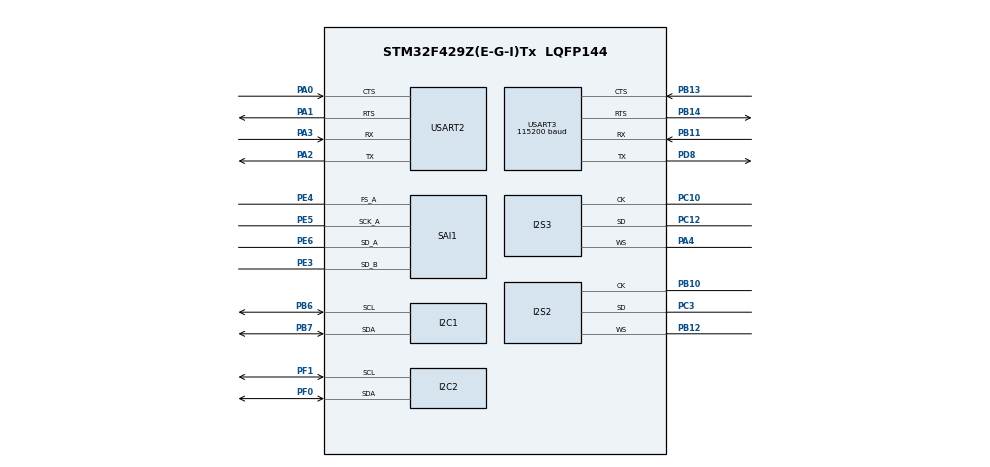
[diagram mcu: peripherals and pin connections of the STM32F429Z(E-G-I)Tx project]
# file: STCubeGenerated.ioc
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Dma.Request0=SPI3_RX
Dma.Request1=SPI2_RX
Dma.Request2=SAI1_A
Dma.Request3=SAI1_B
Dma.SAI1_A.2.Channel=DMA_CHANNEL_0
Dma.SAI1_A.2.Direction=DMA_PERIPH_TO_MEMORY
Dma.SAI1_A.2.FIFOMode=DMA_FIFOMODE_ENABLE
Dma.SAI1_A.2.FIFOThreshold=DMA_FIFO_THRESHOLD_HALFFULL
Dma.SAI1_A.2.Instance=DMA2_Stream1
Dma.SAI1_A.2.MemBurst=DMA_MBURST_SINGLE
Dma.SAI1_A.2.MemDataAlignment=DMA_MDATAALIGN_WORD
Dma.SAI1_A.2.MemInc=DMA_MINC_ENABLE
Dma.SAI1_A.2.Mode=DMA_CIRCULAR
Dma.SAI1_A.2.PeriphBurst=DMA_PBURST_SINGLE
Dma.SAI1_A.2.PeriphDataAlignment=DMA_PDATAALIGN_WORD
Dma.SAI1_A.2.PeriphInc=DMA_PINC_DISABLE
Dma.SAI1_A.2.Priority=DMA_PRIORITY_LOW
Dma.SAI1_B.3.Channel=DMA_CHANNEL_1
Dma.SAI1_B.3.Direction=DMA_PERIPH_TO_MEMORY
Dma.SAI1_B.3.FIFOMode=DMA_FIFOMODE_ENABLE
Dma.SAI1_B.3.FIFOThreshold=DMA_FIFO_THRESHOLD_HALFFULL
Dma.SAI1_B.3.Instance=DMA2_Stream4
Dma.SAI1_B.3.MemBurst=DMA_MBURST_INC4
Dma.SAI1_B.3.MemDataAlignment=DMA_MDATAALIGN_WORD
Dma.SAI1_B.3.MemInc=DMA_MINC_ENABLE
Dma.SAI1_B.3.Mode=DMA_CIRCULAR
Dma.SAI1_B.3.PeriphBurst=DMA_PBURST_INC4
Dma.SAI1_B.3.PeriphDataAlignment=DMA_PDATAALIGN_WORD
Dma.SAI1_B.3.PeriphInc=DMA_PINC_DISABLE
Dma.SAI1_B.3.Priority=DMA_PRIORITY_LOW
Dma.SPI2_RX.1.Channel=DMA_CHANNEL_0
Dma.SPI2_RX.1.Direction=DMA_PERIPH_TO_MEMORY
Dma.SPI2_RX.1.FIFOMode=DMA_FIFOMODE_ENABLE
Dma.SPI2_RX.1.FIFOThreshold=DMA_FIFO_THRESHOLD_HALFFULL
Dma.SPI2_RX.1.Instance=DMA1_Stream3
Dma.SPI2_RX.1.MemBurst=DMA_MBURST_SINGLE
Dma.SPI2_RX.1.MemDataAlignment=DMA_MDATAALIGN_WORD
Dma.SPI2_RX.1.MemInc=DMA_MINC_ENABLE
Dma.SPI2_RX.1.Mode=DMA_CIRCULAR
Dma.SPI2_RX.1.PeriphBurst=DMA_PBURST_SINGLE
Dma.SPI2_RX.1.PeriphDataAlignment=DMA_PDATAALIGN_HALFWORD
Dma.SPI2_RX.1.PeriphInc=DMA_PINC_DISABLE
Dma.SPI2_RX.1.Priority=DMA_PRIORITY_LOW
Dma.SPI3_RX.0.Channel=DMA_CHANNEL_0
Dma.SPI3_RX.0.Direction=DMA_PERIPH_TO_MEMORY
Dma.SPI3_RX.0.FIFOMode=DMA_FIFOMODE_ENABLE
Dma.SPI3_RX.0.FIFOThreshold=DMA_FIFO_THRESHOLD_HALFFULL
Dma.SPI3_RX.0.Instance=DMA1_Stream0
Dma.SPI3_RX.0.MemBurst=DMA_MBURST_SINGLE
Dma.SPI3_RX.0.MemDataAlignment=DMA_MDATAALIGN_WORD
Dma.SPI3_RX.0.MemInc=DMA_MINC_ENABLE
Dma.SPI3_RX.0.Mode=DMA_CIRCULAR
Dma.SPI3_RX.0.PeriphBurst=DMA_PBURST_SINGLE
Dma.SPI3_RX.0.PeriphDataAlignment=DMA_PDATAALIGN_HALFWORD
Dma.SPI3_RX.0.PeriphInc=DMA_PINC_DISABLE
Dma.SPI3_RX.0.Priority=DMA_PRIORITY_LOW
I2S2.AudioFreq=I2S_AUDIOFREQ_48K
I2S2.CPOL=I2S_CPOL_LOW
I2S2.DataFormat=I2S_DATAFORMAT_32B
I2S2.ErrorAudioFreq=0.8 %
I2S2.Mode=I2S_MODE_SLAVE_RX
I2S2.RealAudioFreq=48.387 KHz
I2S2.Standard=I2S_STANDARD_MSB
I2S2.VirtualMode=I2S_MODE_SLAVE
I2S3.AudioFreq=I2S_AUDIOFREQ_48K
I2S3.DataFormat=I2S_DATAFORMAT_32B
I2S3.ErrorAudioFreq=0.8 %
I2S3.Mode=I2S_MODE_SLAVE_RX
I2S3.RealAudioFreq=48.387 KHz
I2S3.Standard=I2S_STANDARD_MSB
I2S3.VirtualMode=I2S_MODE_SLAVE
Mcu.Family=STM32F4
Mcu.Name=STM32F429Z(E-G-I)Tx
Mcu.Package=LQFP144
NVIC.DMA1_Stream0_IRQn=true\:0\:0\:false
NVIC.DMA1_Stream3_IRQn=true\:0\:0\:false
NVIC.DMA2_Stream1_IRQn=true\:0\:0\:false
NVIC.DMA2_Stream4_IRQn=true\:0\:0\:false
NVIC.PriorityGroup=NVIC_PRIORITYGROUP_4
PA0/WKUP.Mode=CTS_RTS
PA0/WKUP.Signal=USART2_CTS
PA1.Mode=CTS_RTS
PA1.Signal=USART2_RTS
PA13.Mode=Serial-Wire
PA13.Signal=SYS_JTMS-SWDIO
PA14.Mode=Serial-Wire
PA14.Signal=SYS_JTCK-SWCLK
PA2.Mode=Asynchronous
PA2.Signal=USART2_TX
PA3.Mode=Asynchronous
PA3.Signal=USART2_RX
PA4.Mode=Half_Duplex_Slave
PA4.Signal=I2S3_WS
PB10.Mode=Half_Duplex_Slave
PB10.Signal=I2S2_CK
PB11.Mode=Asynchronous
PB11.Signal=USART3_RX
PB12.Mode=Half_Duplex_Slave
PB12.Signal=I2S2_WS
PB13.Mode=CTS_RTS
PB13.Signal=USART3_CTS
PB14.Mode=CTS_RTS
PB14.Signal=USART3_RTS
PB6.Mode=I2C
PB6.Signal=I2C1_SCL
PB7.Mode=I2C
PB7.Signal=I2C1_SDA
PC10.Mode=Half_Duplex_Slave
PC10.Signal=I2S3_CK
PC12.Mode=Half_Duplex_Slave
PC12.Signal=I2S3_SD
PC3.Mode=Half_Duplex_Slave
PC3.Signal=I2S2_SD
PD8.Mode=Asynchronous
PD8.Signal=USART3_TX
PE3.Mode=SAI_B_SyncSlave
PE3.Signal=SAI1_SD_B
PE4.Mode=SAI_A_AsyncSlave
PE4.Signal=SAI1_FS_A
PE5.Mode=SAI_A_AsyncSlave
PE5.Signal=SAI1_SCK_A
PE6.Mode=SAI_A_AsyncSlave
PE6.Signal=SAI1_SD_A
PF0.Mode=I2C
PF0.Signal=I2C2_SDA
PF1.Mode=I2C
PF1.Signal=I2C2_SCL
ProjectManager.TargetToolchain=MDK-ARM V4
RCC.48MHZClocksFreq_Value=48000000
RCC.AHBFreq_Value=16000000
RCC.APB1Freq_Value=16000000
RCC.APB2Freq_Value=16000000
RCC.CortexFreq_Value=16000000
RCC.HSE_VALUE=25000000
RCC.HSI_VALUE=16000000
RCC.LSE_VALUE=32768
RCC.PLLSAIN=192
RCC.SYSCLKFreq_VALUE=16000000
RCC.VCOOutputFreq_Value=192000000
SAI1.ActiveFrameLength-SAI_A_AsyncSlave=32
SAI1.ActiveFrameLength-SAI_B_SyncSlave=32
SAI1.ClockStrobing-SAI_A_AsyncSlave=SAI_CLOCKSTROBING_RISINGEDGE
SAI1.ClockStrobing-SAI_B_SyncSlave=SAI_CLOCKSTROBING_RISINGEDGE
SAI1.DataSize-SAI_A_AsyncSlave=SAI_DATASIZE_32
SAI1.DataSize-SAI_B_SyncSlave=SAI_DATASIZE_32
SAI1.FIFOThreshold-SAI_A_AsyncSlave=SAI_FIFOTHRESHOLD_HF
SAI1.FIFOThreshold-SAI_B_SyncSlave=SAI_FIFOTHRESHOLD_HF
SAI1.FSDefinition-SAI_A_AsyncSlave=SAI_FS_CHANNEL_IDENTIFICATION
SAI1.FSDefinition-SAI_B_SyncSlave=SAI_FS_CHANNEL_IDENTIFICATION
SAI1.FrameLength-SAI_A_AsyncSlave=64
SAI1.FrameLength-SAI_B_SyncSlave=64
SAI1.Instance-SAI_A_AsyncSlave=SAI$Index_Block_A
SAI1.Instance-SAI_B_SyncSlave=SAI$Index_Block_B
SAI1.Protocol-SAI_B_SyncSlave=SAI_FREE_PROTOCOL
SAI1.SlotActive-SAI_A_AsyncSlave=0xFFFF0000
SAI1.SlotActive-SAI_B_SyncSlave=0xFFFF0000
SAI1.SlotNumber-SAI_A_AsyncSlave=2
SAI1.SlotNumber-SAI_B_SyncSlave=2
SAI1.SlotSize-SAI_A_AsyncSlave=SAI_SLOTSIZE_32B
SAI1.SlotSize-SAI_B_SyncSlave=SAI_SLOTSIZE_32B
SAI1.Synchro-SAI_B_SyncSlave=SAI_SYNCHRONOUS
SAI1.VirtualMode-SAI_A_AsyncSlave=VM_SLAVE
SAI1.VirtualMode-SAI_B_SyncSlave=VM_SLAVE
SAI1.VirtualSlotActive-SAI_A_AsyncSlave=SAI_SLOTACTIVE_ALL
SAI1.VirtualSlotActive-SAI_B_SyncSlave=SAI_SLOTACTIVE_ALL
SAI1.VirtualSlotActive0-SAI_A_AsyncSlave=true
SAI1.VirtualSlotActive0-SAI_B_SyncSlave=false
SAI1.VirtualSlotActive1-SAI_B_SyncSlave=true
USART3.BaudRate=115200

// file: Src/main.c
/**
  ******************************************************************************
  * File Name          : main.c
  * Description        : Main program body
  ******************************************************************************
  *
  * COPYRIGHT(c) 2015 STMicroelectronics
  *
  * Redistribution and use in source and binary forms, with or without modification,
  * are permitted provided that the following conditions are met:
  *   1. Redistributions of source code must retain the above copyright notice,
  *      this list of conditions and the following disclaimer.
  *   2. Redistributions in binary form must reproduce the above copyright notice,
  *      this list of conditions and the following disclaimer in the documentation
  *      and/or other materials provided with the distribution.
  *   3. Neither the name of STMicroelectronics nor the names of its contributors
  *      may be used to endorse or promote products derived from this software
  *      without specific prior written permission.
  *
  * THIS SOFTWARE IS PROVIDED BY THE COPYRIGHT HOLDERS AND CONTRIBUTORS "AS IS"
  * AND ANY EXPRESS OR IMPLIED WARRANTIES, INCLUDING, BUT NOT LIMITED TO, THE
  * IMPLIED WARRANTIES OF MERCHANTABILITY AND FITNESS FOR A PARTICULAR PURPOSE ARE
  * DISCLAIMED. IN NO EVENT SHALL THE COPYRIGHT HOLDER OR CONTRIBUTORS BE LIABLE
  * FOR ANY DIRECT, INDIRECT, INCIDENTAL, SPECIAL, EXEMPLARY, OR CONSEQUENTIAL
  * DAMAGES (INCLUDING, BUT NOT LIMITED TO, PROCUREMENT OF SUBSTITUTE GOODS OR
  * SERVICES; LOSS OF USE, DATA, OR PROFITS; OR BUSINESS INTERRUPTION) HOWEVER
  * CAUSED AND ON ANY THEORY OF LIABILITY, WHETHER IN CONTRACT, STRICT LIABILITY,
  * OR TORT (INCLUDING NEGLIGENCE OR OTHERWISE) ARISING IN ANY WAY OUT OF THE USE
  * OF THIS SOFTWARE, EVEN IF ADVISED OF THE POSSIBILITY OF SUCH DAMAGE.
  *
  ******************************************************************************
  */

#include "stm32f4xx_hal.h"

/* USER CODE BEGIN Includes */
#include "Putz01.h"
/* USER CODE END Includes */

I2C_HandleTypeDef hi2c1;
I2C_HandleTypeDef hi2c2;

I2S_HandleTypeDef hi2s2;
I2S_HandleTypeDef hi2s3;
DMA_HandleTypeDef hdma_spi2_rx;
DMA_HandleTypeDef hdma_spi3_rx;

SAI_HandleTypeDef hsai_BlockA1;
SAI_HandleTypeDef hsai_BlockB1;
DMA_HandleTypeDef hdma_sai1_a;
DMA_HandleTypeDef hdma_sai1_b;

UART_HandleTypeDef huart2;
UART_HandleTypeDef huart3;

void SystemClock_Config(void);
static void MX_GPIO_Init(void);
static void MX_DMA_Init(void);
static void MX_I2C1_Init(void);
static void MX_I2C2_Init(void);
static void MX_I2S2_Init(void);
static void MX_I2S3_Init(void);
static void MX_SAI1_Init(void);
static void MX_USART2_UART_Init(void);
static void MX_USART3_UART_Init(void);

int main(void)
{

  /* MCU Configuration----------------------------------------------------------*/

  /* Reset of all peripherals, Initializes the Flash interface and the Systick. */
  HAL_Init();

  /* Configure the system clock */
  SystemClock_Config();

  /* Initialize all configured peripherals */
  MX_GPIO_Init();
  MX_DMA_Init();
  MX_I2C1_Init();
  MX_I2C2_Init();
  MX_I2S2_Init();
  MX_I2S3_Init();
  MX_SAI1_Init();
  MX_USART2_UART_Init();
  MX_USART3_UART_Init();

  /* USER CODE BEGIN 2 */
	Putz01Init();

  /* USER CODE END 2 */

  /* Infinite loop */
  while (1)
  {
	Putz01Run();

  }

}

/** System Clock Configuration
*/
void SystemClock_Config(void)
{

  RCC_OscInitTypeDef RCC_OscInitStruct;
  RCC_PeriphCLKInitTypeDef PeriphClkInitStruct;

  __HAL_RCC_PLL_PLLM_CONFIG(16);

  __HAL_RCC_PLL_PLLSOURCE_CONFIG(RCC_PLLSOURCE_HSI);

  __PWR_CLK_ENABLE();

  __HAL_PWR_VOLTAGESCALING_CONFIG(PWR_REGULATOR_VOLTAGE_SCALE3);

  RCC_OscInitStruct.OscillatorType = RCC_OSCILLATORTYPE_HSI;
  RCC_OscInitStruct.HSIState = RCC_HSI_ON;
  RCC_OscInitStruct.HSICalibrationValue = 16;
  RCC_OscInitStruct.PLL.PLLState = RCC_PLL_NONE;
  HAL_RCC_OscConfig(&RCC_OscInitStruct);

  PeriphClkInitStruct.PeriphClockSelection = RCC_PERIPHCLK_I2S|RCC_PERIPHCLK_SAI_PLLSAI;
  PeriphClkInitStruct.PLLI2S.PLLI2SN = 192;
  PeriphClkInitStruct.PLLI2S.PLLI2SR = 2;
  PeriphClkInitStruct.PLLSAI.PLLSAIN = 192;
  PeriphClkInitStruct.PLLSAI.PLLSAIQ = 4;
  PeriphClkInitStruct.PLLSAIDivQ = 1;
  HAL_RCCEx_PeriphCLKConfig(&PeriphClkInitStruct);

  HAL_SYSTICK_Config(HAL_RCC_GetHCLKFreq()/1000);

  HAL_SYSTICK_CLKSourceConfig(SYSTICK_CLKSOURCE_HCLK);

}

/* I2C1 init function */
void MX_I2C1_Init(void)
{

  hi2c1.Instance = I2C1;
  hi2c1.Init.ClockSpeed = 100000;
  hi2c1.Init.DutyCycle = I2C_DUTYCYCLE_2;
  hi2c1.Init.OwnAddress1 = 0;
  hi2c1.Init.AddressingMode = I2C_ADDRESSINGMODE_7BIT;
  hi2c1.Init.DualAddressMode = I2C_DUALADDRESS_DISABLED;
  hi2c1.Init.OwnAddress2 = 0;
  hi2c1.Init.GeneralCallMode = I2C_GENERALCALL_DISABLED;
  hi2c1.Init.NoStretchMode = I2C_NOSTRETCH_DISABLED;
  HAL_I2C_Init(&hi2c1);

}

/* I2C2 init function */
void MX_I2C2_Init(void)
{

  hi2c2.Instance = I2C2;
  hi2c2.Init.ClockSpeed = 100000;
  hi2c2.Init.DutyCycle = I2C_DUTYCYCLE_2;
  hi2c2.Init.OwnAddress1 = 0;
  hi2c2.Init.AddressingMode = I2C_ADDRESSINGMODE_7BIT;
  hi2c2.Init.DualAddressMode = I2C_DUALADDRESS_DISABLED;
  hi2c2.Init.OwnAddress2 = 0;
  hi2c2.Init.GeneralCallMode = I2C_GENERALCALL_DISABLED;
  hi2c2.Init.NoStretchMode = I2C_NOSTRETCH_DISABLED;
  HAL_I2C_Init(&hi2c2);

}

/* I2S2 init function */
void MX_I2S2_Init(void)
{

  hi2s2.Instance = SPI2;
  hi2s2.Init.Mode = I2S_MODE_SLAVE_RX;
  hi2s2.Init.Standard = I2S_STANDARD_MSB;
  hi2s2.Init.DataFormat = I2S_DATAFORMAT_32B;
  hi2s2.Init.MCLKOutput = I2S_MCLKOUTPUT_DISABLE;
  hi2s2.Init.AudioFreq = I2S_AUDIOFREQ_48K;
  hi2s2.Init.CPOL = I2S_CPOL_LOW;
  hi2s2.Init.ClockSource = I2S_CLOCK_PLL;
  hi2s2.Init.FullDuplexMode = I2S_FULLDUPLEXMODE_DISABLE;
  HAL_I2S_Init(&hi2s2);

}

/* I2S3 init function */
void MX_I2S3_Init(void)
{

  hi2s3.Instance = SPI3;
  hi2s3.Init.Mode = I2S_MODE_SLAVE_RX;
  hi2s3.Init.Standard = I2S_STANDARD_MSB;
  hi2s3.Init.DataFormat = I2S_DATAFORMAT_32B;
  hi2s3.Init.MCLKOutput = I2S_MCLKOUTPUT_DISABLE;
  hi2s3.Init.AudioFreq = I2S_AUDIOFREQ_48K;
  hi2s3.Init.CPOL = I2S_CPOL_LOW;
  hi2s3.Init.ClockSource = I2S_CLOCK_PLL;
  hi2s3.Init.FullDuplexMode = I2S_FULLDUPLEXMODE_DISABLE;
  HAL_I2S_Init(&hi2s3);

}

/* SAI1 init function */
void MX_SAI1_Init(void)
{

  hsai_BlockA1.Instance = SAI1_Block_A;
  hsai_BlockA1.Init.Protocol = SAI_FREE_PROTOCOL;
  hsai_BlockA1.Init.AudioMode = SAI_MODESLAVE_RX;
  hsai_BlockA1.Init.DataSize = SAI_DATASIZE_32;
  hsai_BlockA1.Init.FirstBit = SAI_FIRSTBIT_MSB;
  hsai_BlockA1.Init.ClockStrobing = SAI_CLOCKSTROBING_RISINGEDGE;
  hsai_BlockA1.Init.Synchro = SAI_ASYNCHRONOUS;
  hsai_BlockA1.Init.OutputDrive = SAI_OUTPUTDRIVE_DISABLED;
  hsai_BlockA1.Init.FIFOThreshold = SAI_FIFOTHRESHOLD_HF;
  hsai_BlockA1.FrameInit.FrameLength = 64;
  hsai_BlockA1.FrameInit.ActiveFrameLength = 32;
  hsai_BlockA1.FrameInit.FSDefinition = SAI_FS_CHANNEL_IDENTIFICATION;
  hsai_BlockA1.FrameInit.FSPolarity = SAI_FS_ACTIVE_HIGH;//SAI_FS_ACTIVE_LOW;
  hsai_BlockA1.FrameInit.FSOffset = SAI_FS_FIRSTBIT;
  hsai_BlockA1.SlotInit.FirstBitOffset = 0;
  hsai_BlockA1.SlotInit.SlotSize = SAI_SLOTSIZE_32B;
  hsai_BlockA1.SlotInit.SlotNumber = 2;
  hsai_BlockA1.SlotInit.SlotActive = 0xFFFF0000;
  HAL_SAI_Init(&hsai_BlockA1);

  hsai_BlockB1.Instance = SAI1_Block_B;
  hsai_BlockB1.Init.Protocol = SAI_FREE_PROTOCOL;
  hsai_BlockB1.Init.AudioMode = SAI_MODESLAVE_RX;
  hsai_BlockB1.Init.DataSize = SAI_DATASIZE_32;
  hsai_BlockB1.Init.FirstBit = SAI_FIRSTBIT_MSB;
  hsai_BlockB1.Init.ClockStrobing = SAI_CLOCKSTROBING_RISINGEDGE;
  hsai_BlockB1.Init.Synchro = SAI_SYNCHRONOUS;
  hsai_BlockB1.Init.OutputDrive = SAI_OUTPUTDRIVE_DISABLED;
  hsai_BlockB1.Init.FIFOThreshold = SAI_FIFOTHRESHOLD_HF;
  hsai_BlockB1.FrameInit.FrameLength = 64;
  hsai_BlockB1.FrameInit.ActiveFrameLength = 32;
  hsai_BlockB1.FrameInit.FSDefinition = SAI_FS_CHANNEL_IDENTIFICATION;
  hsai_BlockB1.FrameInit.FSPolarity = SAI_FS_ACTIVE_HIGH;//SAI_FS_ACTIVE_LOW;
  hsai_BlockB1.FrameInit.FSOffset = SAI_FS_FIRSTBIT;
  hsai_BlockB1.SlotInit.FirstBitOffset = 0;
  hsai_BlockB1.SlotInit.SlotSize = SAI_SLOTSIZE_32B;
  hsai_BlockB1.SlotInit.SlotNumber = 2;
  hsai_BlockB1.SlotInit.SlotActive = 0xFFFF0000;
  HAL_SAI_Init(&hsai_BlockB1);

}

/* USART2 init function */
void MX_USART2_UART_Init(void)
{

  huart2.Instance = USART2;
  huart2.Init.BaudRate = 115200;
  huart2.Init.WordLength = UART_WORDLENGTH_8B;
  huart2.Init.StopBits = UART_STOPBITS_1;
  huart2.Init.Parity = UART_PARITY_NONE;
  huart2.Init.Mode = UART_MODE_TX_RX;
  huart2.Init.HwFlowCtl = UART_HWCONTROL_RTS_CTS;
  huart2.Init.OverSampling = UART_OVERSAMPLING_16;
  HAL_UART_Init(&huart2);

}

/* USART3 init function */
void MX_USART3_UART_Init(void)
{

  huart3.Instance = USART3;
  huart3.Init.BaudRate = 115200;
  huart3.Init.WordLength = UART_WORDLENGTH_8B;
  huart3.Init.StopBits = UART_STOPBITS_1;
  huart3.Init.Parity = UART_PARITY_NONE;
  huart3.Init.Mode = UART_MODE_TX_RX;
  huart3.Init.HwFlowCtl = UART_HWCONTROL_RTS_CTS;
  huart3.Init.OverSampling = UART_OVERSAMPLING_16;
  HAL_UART_Init(&huart3);

}

void MX_DMA_Init(void)
{
  /* DMA controller clock enable */
  __DMA1_CLK_ENABLE();
  __DMA2_CLK_ENABLE();

  /* DMA interrupt init */
  HAL_NVIC_SetPriority(DMA1_Stream0_IRQn, 0, 0);
  HAL_NVIC_EnableIRQ(DMA1_Stream0_IRQn);
  HAL_NVIC_SetPriority(DMA1_Stream3_IRQn, 0, 0);
  HAL_NVIC_EnableIRQ(DMA1_Stream3_IRQn);
  HAL_NVIC_SetPriority(DMA2_Stream1_IRQn, 0, 0);
  HAL_NVIC_EnableIRQ(DMA2_Stream1_IRQn);
  HAL_NVIC_SetPriority(DMA2_Stream4_IRQn, 0, 0);
  HAL_NVIC_EnableIRQ(DMA2_Stream4_IRQn);

}

/** Configure pins as
        * Analog
        * Input
        * Output
        * EVENT_OUT
        * EXTI
*/
void MX_GPIO_Init(void)
{

  /* GPIO Ports Clock Enable */
  __GPIOE_CLK_ENABLE();
  __GPIOF_CLK_ENABLE();
  __GPIOC_CLK_ENABLE();
  __GPIOA_CLK_ENABLE();
  __GPIOB_CLK_ENABLE();
  __GPIOD_CLK_ENABLE();

}

#ifdef USE_FULL_ASSERT

/**
   * @brief Reports the name of the source file and the source line number
   * where the assert_param error has occurred.
   * @param file: pointer to the source file name
   * @param line: assert_param error line source number
   * @retval None
   */
void assert_failed(uint8_t* file, uint32_t line)
{
  /* USER CODE BEGIN 6 */
  /* User can add his own implementation to report the file name and line number,
    ex: printf("Wrong parameters value: file %s on line %d\r\n", file, line) */

	Putz01Assert(file, line);

  /* USER CODE END 6 */

}

#endif

/************************ (C) COPYRIGHT STMicroelectronics *****END OF FILE****/
